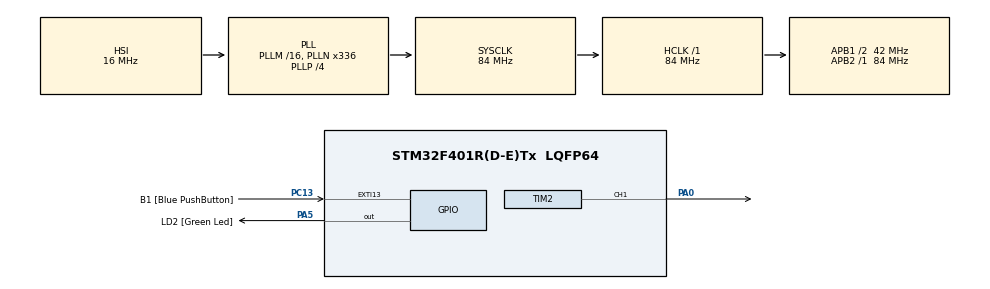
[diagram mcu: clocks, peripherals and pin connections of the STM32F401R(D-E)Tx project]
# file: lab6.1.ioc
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Dma.MEMTOMEM.0.Direction=DMA_MEMORY_TO_MEMORY
Dma.MEMTOMEM.0.FIFOMode=DMA_FIFOMODE_ENABLE
Dma.MEMTOMEM.0.FIFOThreshold=DMA_FIFO_THRESHOLD_FULL
Dma.MEMTOMEM.0.Instance=DMA2_Stream0
Dma.MEMTOMEM.0.MemBurst=DMA_MBURST_SINGLE
Dma.MEMTOMEM.0.MemDataAlignment=DMA_MDATAALIGN_BYTE
Dma.MEMTOMEM.0.MemInc=DMA_MINC_ENABLE
Dma.MEMTOMEM.0.Mode=DMA_NORMAL
Dma.MEMTOMEM.0.PeriphBurst=DMA_PBURST_SINGLE
Dma.MEMTOMEM.0.PeriphDataAlignment=DMA_PDATAALIGN_BYTE
Dma.MEMTOMEM.0.PeriphInc=DMA_PINC_ENABLE
Dma.MEMTOMEM.0.Priority=DMA_PRIORITY_LOW
Dma.Request0=MEMTOMEM
Dma.Request1=TIM2_CH1
Dma.TIM2_CH1.1.Direction=DMA_PERIPH_TO_MEMORY
Dma.TIM2_CH1.1.FIFOMode=DMA_FIFOMODE_DISABLE
Dma.TIM2_CH1.1.Instance=DMA1_Stream5
Dma.TIM2_CH1.1.MemDataAlignment=DMA_MDATAALIGN_WORD
Dma.TIM2_CH1.1.MemInc=DMA_MINC_ENABLE
Dma.TIM2_CH1.1.Mode=DMA_NORMAL
Dma.TIM2_CH1.1.PeriphDataAlignment=DMA_PDATAALIGN_WORD
Dma.TIM2_CH1.1.PeriphInc=DMA_PINC_DISABLE
Dma.TIM2_CH1.1.Priority=DMA_PRIORITY_LOW
Mcu.Family=STM32F4
Mcu.Name=STM32F401R(D-E)Tx
Mcu.Package=LQFP64
NVIC.DMA1_Stream5_IRQn=true\:0\:0\:false\:false\:true\:false\:true\:true
NVIC.PriorityGroup=NVIC_PRIORITYGROUP_4
PA0-WKUP.Signal=S_TIM2_CH1_ETR
PA13.GPIO_Label=TMS
PA13.Mode=Trace_Asynchronous_SW
PA13.Signal=SYS_JTMS-SWDIO
PA14.GPIO_Label=TCK
PA14.Mode=Trace_Asynchronous_SW
PA14.Signal=SYS_JTCK-SWCLK
PA5.GPIO_Label=LD2 [Green Led]
PA5.GPIO_Mode=GPIO_MODE_OUTPUT_PP
PA5.GPIO_PuPd=GPIO_NOPULL
PA5.GPIO_Speed=GPIO_SPEED_FREQ_LOW
PA5.Signal=GPIO_Output
PB3.GPIO_Label=SWO
PB3.Mode=Trace_Asynchronous_SW
PB3.Signal=SYS_JTDO-SWO
PC13-ANTI_TAMP.GPIO_Label=B1 [Blue PushButton]
PC13-ANTI_TAMP.GPIO_ModeDefaultEXTI=GPIO_MODE_IT_FALLING
PC13-ANTI_TAMP.GPIO_PuPd=GPIO_NOPULL
PC13-ANTI_TAMP.Signal=GPXTI13
PC14-OSC32_IN.Mode=LSE-External-Oscillator
PC14-OSC32_IN.Signal=RCC_OSC32_IN
PC15-OSC32_OUT.Mode=LSE-External-Oscillator
PC15-OSC32_OUT.Signal=RCC_OSC32_OUT
PH0\ -\ OSC_IN.Mode=HSE-External-Oscillator
PH0\ -\ OSC_IN.Signal=RCC_OSC_IN
PH1\ -\ OSC_OUT.Mode=HSE-External-Oscillator
PH1\ -\ OSC_OUT.Signal=RCC_OSC_OUT
ProjectManager.HeapSize=0x200
ProjectManager.StackSize=0x400
ProjectManager.TargetToolchain=STM32CubeIDE
RCC.48MHZClocksFreq_Value=48000000
RCC.AHBFreq_Value=84000000
RCC.APB1CLKDivider=RCC_HCLK_DIV2
RCC.APB1Freq_Value=42000000
RCC.APB1TimFreq_Value=84000000
RCC.APB2Freq_Value=84000000
RCC.APB2TimFreq_Value=84000000
RCC.CortexFreq_Value=84000000
RCC.HCLKFreq_Value=84000000
RCC.HSE_VALUE=8000000
RCC.HSI_VALUE=16000000
RCC.PLLN=336
RCC.PLLP=RCC_PLLP_DIV4
RCC.PLLQ=7
RCC.SYSCLKFreq_VALUE=84000000
RCC.SYSCLKSource=RCC_SYSCLKSOURCE_PLLCLK
RCC.VCOOutputFreq_Value=336000000
SH.S_TIM2_CH1_ETR.0=TIM2_CH1,PWM Generation1 CH1
TIM2.Channel-PWM\ Generation1\ CH1=TIM_CHANNEL_1
board=NUCLEO-F401RE

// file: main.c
/* USER CODE BEGIN Header */
/**
  ******************************************************************************
  * @file           : main.c
  * @brief          : Main program body
  ******************************************************************************
  * @attention
  *
  * Copyright (c) 2026 STMicroelectronics.
  * All rights reserved.
  *
  * This software is licensed under terms that can be found in the LICENSE file
  * in the root directory of this software component.
  * If no LICENSE file comes with this software, it is provided AS-IS.
  *
  ******************************************************************************
  */
/* USER CODE END Header */
#include "main.h"

TIM_HandleTypeDef htim2;
DMA_HandleTypeDef hdma_tim2_ch1;

DMA_HandleTypeDef hdma_memtomem_dma2_stream0;
/* USER CODE BEGIN PV */
const uint32_t sourceData[] = {0x11111111, 0x22222222, 0x33333333, 0x44444444};
uint32_t destData[4];
/* USER CODE END PV */

void SystemClock_Config(void);
static void MX_GPIO_Init(void);
static void MX_DMA_Init(void);
static void MX_TIM2_Init(void);

int main(void)
{

  /* MCU Configuration--------------------------------------------------------*/

  /* Reset of all peripherals, Initializes the Flash interface and the Systick. */
  HAL_Init();

  /* Configure the system clock */
  SystemClock_Config();

  /* Initialize all configured peripherals */
  MX_GPIO_Init();
  MX_DMA_Init();
  MX_TIM2_Init();
  /* USER CODE BEGIN 2 */
  HAL_DMA_Start(&hdma_memtomem_dma2_stream0, (uint32_t)sourceData, (uint32_t)destData, 4);
  /* USER CODE END 2 */

  /* Infinite loop */
  while (1)
  {

  }
}

void SystemClock_Config(void)
{
  RCC_OscInitTypeDef RCC_OscInitStruct = {0};
  RCC_ClkInitTypeDef RCC_ClkInitStruct = {0};

  /** Configure the main internal regulator output voltage
  */
  __HAL_RCC_PWR_CLK_ENABLE();
  __HAL_PWR_VOLTAGESCALING_CONFIG(PWR_REGULATOR_VOLTAGE_SCALE2);

  /** Initializes the RCC Oscillators according to the specified parameters
  * in the RCC_OscInitTypeDef structure.
  */
  RCC_OscInitStruct.OscillatorType = RCC_OSCILLATORTYPE_HSI;
  RCC_OscInitStruct.HSIState = RCC_HSI_ON;
  RCC_OscInitStruct.HSICalibrationValue = RCC_HSICALIBRATION_DEFAULT;
  RCC_OscInitStruct.PLL.PLLState = RCC_PLL_ON;
  RCC_OscInitStruct.PLL.PLLSource = RCC_PLLSOURCE_HSI;
  RCC_OscInitStruct.PLL.PLLM = 16;
  RCC_OscInitStruct.PLL.PLLN = 336;
  RCC_OscInitStruct.PLL.PLLP = RCC_PLLP_DIV4;
  RCC_OscInitStruct.PLL.PLLQ = 7;
  if (HAL_RCC_OscConfig(&RCC_OscInitStruct) != HAL_OK)
  {
    Error_Handler();
  }

  /** Initializes the CPU, AHB and APB buses clocks
  */
  RCC_ClkInitStruct.ClockType = RCC_CLOCKTYPE_HCLK|RCC_CLOCKTYPE_SYSCLK
                              |RCC_CLOCKTYPE_PCLK1|RCC_CLOCKTYPE_PCLK2;
  RCC_ClkInitStruct.SYSCLKSource = RCC_SYSCLKSOURCE_PLLCLK;
  RCC_ClkInitStruct.AHBCLKDivider = RCC_SYSCLK_DIV1;
  RCC_ClkInitStruct.APB1CLKDivider = RCC_HCLK_DIV2;
  RCC_ClkInitStruct.APB2CLKDivider = RCC_HCLK_DIV1;

  if (HAL_RCC_ClockConfig(&RCC_ClkInitStruct, FLASH_LATENCY_2) != HAL_OK)
  {
    Error_Handler();
  }
}

static void MX_TIM2_Init(void)
{

  TIM_MasterConfigTypeDef sMasterConfig = {0};
  TIM_OC_InitTypeDef sConfigOC = {0};

  htim2.Instance = TIM2;
  htim2.Init.Prescaler = 0;
  htim2.Init.CounterMode = TIM_COUNTERMODE_UP;
  htim2.Init.Period = 4294967295;
  htim2.Init.ClockDivision = TIM_CLOCKDIVISION_DIV1;
  htim2.Init.AutoReloadPreload = TIM_AUTORELOAD_PRELOAD_DISABLE;
  if (HAL_TIM_PWM_Init(&htim2) != HAL_OK)
  {
    Error_Handler();
  }
  sMasterConfig.MasterOutputTrigger = TIM_TRGO_RESET;
  sMasterConfig.MasterSlaveMode = TIM_MASTERSLAVEMODE_DISABLE;
  if (HAL_TIMEx_MasterConfigSynchronization(&htim2, &sMasterConfig) != HAL_OK)
  {
    Error_Handler();
  }
  sConfigOC.OCMode = TIM_OCMODE_PWM1;
  sConfigOC.Pulse = 0;
  sConfigOC.OCPolarity = TIM_OCPOLARITY_HIGH;
  sConfigOC.OCFastMode = TIM_OCFAST_DISABLE;
  if (HAL_TIM_PWM_ConfigChannel(&htim2, &sConfigOC, TIM_CHANNEL_1) != HAL_OK)
  {
    Error_Handler();
  }
  HAL_TIM_MspPostInit(&htim2);

}

static void MX_DMA_Init(void)
{

  /* DMA controller clock enable */
  __HAL_RCC_DMA2_CLK_ENABLE();
  __HAL_RCC_DMA1_CLK_ENABLE();

  /* Configure DMA request hdma_memtomem_dma2_stream0 on DMA2_Stream0 */
  hdma_memtomem_dma2_stream0.Instance = DMA2_Stream0;
  hdma_memtomem_dma2_stream0.Init.Channel = DMA_CHANNEL_0;
  hdma_memtomem_dma2_stream0.Init.Direction = DMA_MEMORY_TO_MEMORY;
  hdma_memtomem_dma2_stream0.Init.PeriphInc = DMA_PINC_ENABLE;
  hdma_memtomem_dma2_stream0.Init.MemInc = DMA_MINC_ENABLE;
  hdma_memtomem_dma2_stream0.Init.PeriphDataAlignment = DMA_PDATAALIGN_BYTE;
  hdma_memtomem_dma2_stream0.Init.MemDataAlignment = DMA_MDATAALIGN_BYTE;
  hdma_memtomem_dma2_stream0.Init.Mode = DMA_NORMAL;
  hdma_memtomem_dma2_stream0.Init.Priority = DMA_PRIORITY_LOW;
  hdma_memtomem_dma2_stream0.Init.FIFOMode = DMA_FIFOMODE_ENABLE;
  hdma_memtomem_dma2_stream0.Init.FIFOThreshold = DMA_FIFO_THRESHOLD_FULL;
  hdma_memtomem_dma2_stream0.Init.MemBurst = DMA_MBURST_SINGLE;
  hdma_memtomem_dma2_stream0.Init.PeriphBurst = DMA_PBURST_SINGLE;
  if (HAL_DMA_Init(&hdma_memtomem_dma2_stream0) != HAL_OK)
  {
    Error_Handler( );
  }

  /* DMA interrupt init */
  /* DMA1_Stream5_IRQn interrupt configuration */
  HAL_NVIC_SetPriority(DMA1_Stream5_IRQn, 0, 0);
  HAL_NVIC_EnableIRQ(DMA1_Stream5_IRQn);

}

static void MX_GPIO_Init(void)
{
  GPIO_InitTypeDef GPIO_InitStruct = {0};

  /* GPIO Ports Clock Enable */
  __HAL_RCC_GPIOC_CLK_ENABLE();
  __HAL_RCC_GPIOH_CLK_ENABLE();
  __HAL_RCC_GPIOA_CLK_ENABLE();
  __HAL_RCC_GPIOB_CLK_ENABLE();

  /*Configure GPIO pin Output Level */
  HAL_GPIO_WritePin(LD2_GPIO_Port, LD2_Pin, GPIO_PIN_RESET);

  /*Configure GPIO pin : B1_Pin */
  GPIO_InitStruct.Pin = B1_Pin;
  GPIO_InitStruct.Mode = GPIO_MODE_IT_FALLING;
  GPIO_InitStruct.Pull = GPIO_NOPULL;
  HAL_GPIO_Init(B1_GPIO_Port, &GPIO_InitStruct);

  /*Configure GPIO pin : LD2_Pin */
  GPIO_InitStruct.Pin = LD2_Pin;
  GPIO_InitStruct.Mode = GPIO_MODE_OUTPUT_PP;
  GPIO_InitStruct.Pull = GPIO_NOPULL;
  GPIO_InitStruct.Speed = GPIO_SPEED_FREQ_LOW;
  HAL_GPIO_Init(LD2_GPIO_Port, &GPIO_InitStruct);

}

void Error_Handler(void)
{
  __disable_irq();
  while (1)
  {
  }
}
